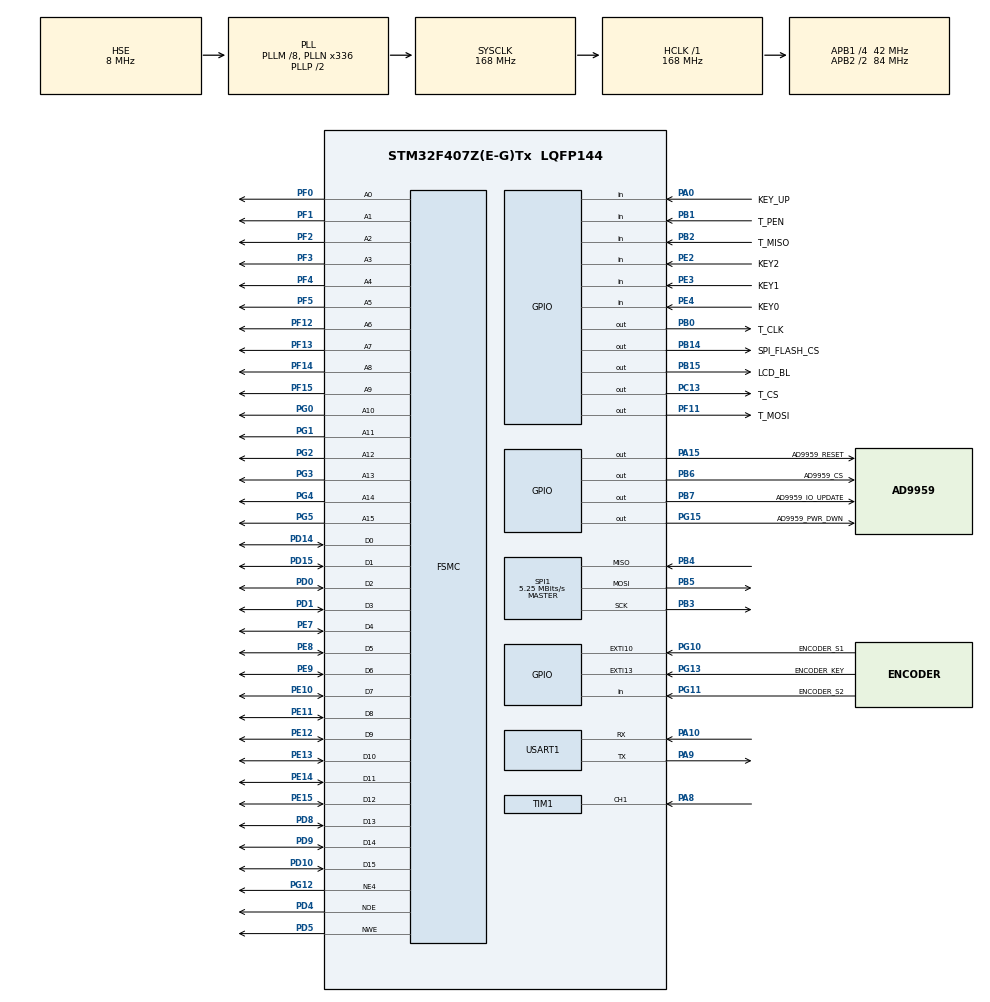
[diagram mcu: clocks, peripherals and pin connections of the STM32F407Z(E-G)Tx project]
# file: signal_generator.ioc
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FSMC.DataSetupTime4=60
FSMC.ExtendedAddressSetupTime4=9
FSMC.ExtendedDataSetupTime4=9
FSMC.ExtendedMode4=FSMC_EXTENDED_MODE_ENABLE
FSMC.WriteOperation4=FSMC_WRITE_OPERATION_ENABLE
Mcu.Family=STM32F4
Mcu.Name=STM32F407Z(E-G)Tx
Mcu.Package=LQFP144
NVIC.EXTI15_10_IRQn=true\:0\:0\:false\:false\:true\:true\:true\:true
NVIC.PriorityGroup=NVIC_PRIORITYGROUP_4
NVIC.TIM1_CC_IRQn=true\:0\:0\:false\:false\:true\:true\:true\:true
PA0-WKUP.GPIO_Label=KEY_UP
PA0-WKUP.GPIO_PuPd=GPIO_PULLDOWN
PA0-WKUP.Signal=GPIO_Input
PA10.Mode=Asynchronous
PA10.Signal=USART1_RX
PA13.Mode=Serial_Wire
PA13.Signal=SYS_JTMS-SWDIO
PA14.Mode=Serial_Wire
PA14.Signal=SYS_JTCK-SWCLK
PA15.GPIO_Label=AD9959_RESET
PA15.Signal=GPIO_Output
PA8.Signal=S_TIM1_CH1
PA9.Mode=Asynchronous
PA9.Signal=USART1_TX
PB0.GPIO_Label=T_CLK
PB0.GPIO_Speed=GPIO_SPEED_FREQ_HIGH
PB0.Signal=GPIO_Output
PB1.GPIO_Label=T_PEN
PB1.GPIO_PuPd=GPIO_PULLUP
PB1.Signal=GPIO_Input
PB14.GPIO_Label=SPI_FLASH_CS
PB14.PinState=GPIO_PIN_SET
PB14.Signal=GPIO_Output
PB15.GPIO_Label=LCD_BL
PB15.Signal=GPIO_Output
PB2.GPIO_Label=T_MISO
PB2.GPIO_PuPd=GPIO_PULLUP
PB2.Signal=GPIO_Input
PB3.Mode=Full_Duplex_Master
PB3.Signal=SPI1_SCK
PB4.Mode=Full_Duplex_Master
PB4.Signal=SPI1_MISO
PB4.Stacked=true
PB5.Mode=Full_Duplex_Master
PB5.Signal=SPI1_MOSI
PB6.GPIO_Label=AD9959_CS
PB6.PinState=GPIO_PIN_SET
PB6.Signal=GPIO_Output
PB7.GPIO_Label=AD9959_IO_UPDATE
PB7.PinState=GPIO_PIN_SET
PB7.Signal=GPIO_Output
PC13-ANTI_TAMP.GPIO_Label=T_CS
PC13-ANTI_TAMP.PinState=GPIO_PIN_SET
PC13-ANTI_TAMP.Signal=GPIO_Output
PC14-OSC32_IN.Mode=LSE-External-Oscillator
PC14-OSC32_IN.Signal=RCC_OSC32_IN
PC15-OSC32_OUT.Mode=LSE-External-Oscillator
PC15-OSC32_OUT.Signal=RCC_OSC32_OUT
PD0.Signal=FSMC_D2_DA2
PD1.Signal=FSMC_D3_DA3
PD10.Signal=FSMC_D15_DA15
PD14.Signal=FSMC_D0_DA0
PD15.Signal=FSMC_D1_DA1
PD4.Signal=FSMC_NOE
PD5.Signal=FSMC_NWE
PD8.Signal=FSMC_D13_DA13
PD9.Signal=FSMC_D14_DA14
PE10.Signal=FSMC_D7_DA7
PE11.Signal=FSMC_D8_DA8
PE12.Signal=FSMC_D9_DA9
PE13.Signal=FSMC_D10_DA10
PE14.Signal=FSMC_D11_DA11
PE15.Signal=FSMC_D12_DA12
PE2.GPIO_Label=KEY2
PE2.GPIO_PuPd=GPIO_PULLUP
PE2.Signal=GPIO_Input
PE3.GPIO_Label=KEY1
PE3.GPIO_PuPd=GPIO_PULLUP
PE3.Signal=GPIO_Input
PE4.GPIO_Label=KEY0
PE4.GPIO_PuPd=GPIO_PULLUP
PE4.Signal=GPIO_Input
PE7.Signal=FSMC_D4_DA4
PE8.Signal=FSMC_D5_DA5
PE9.Signal=FSMC_D6_DA6
PF0.Signal=FSMC_A0
PF1.Signal=FSMC_A1
PF11.GPIO_Label=T_MOSI
PF11.GPIO_Speed=GPIO_SPEED_FREQ_HIGH
PF11.Signal=GPIO_Output
PF12.Signal=FSMC_A6
PF13.Signal=FSMC_A7
PF14.Signal=FSMC_A8
PF15.Signal=FSMC_A9
PF2.Signal=FSMC_A2
PF3.Signal=FSMC_A3
PF4.Signal=FSMC_A4
PF5.Signal=FSMC_A5
PG0.Signal=FSMC_A10
PG1.Signal=FSMC_A11
PG10.GPIO_Label=ENCODER_S1
PG10.GPIO_ModeDefaultEXTI=GPIO_MODE_IT_FALLING
PG10.GPIO_PuPd=GPIO_PULLUP
PG10.Signal=GPXTI10
PG11.GPIO_Label=ENCODER_S2
PG11.GPIO_PuPd=GPIO_PULLUP
PG11.Signal=GPIO_Input
PG12.Mode=NorPsramChipSelect4_4
PG12.Signal=FSMC_NE4
PG13.GPIO_Label=ENCODER_KEY
PG13.GPIO_ModeDefaultEXTI=GPIO_MODE_IT_FALLING
PG13.GPIO_PuPd=GPIO_PULLUP
PG13.Signal=GPXTI13
PG15.GPIO_Label=AD9959_PWR_DWN
PG15.Signal=GPIO_Output
PG2.Signal=FSMC_A12
PG3.Signal=FSMC_A13
PG4.Signal=FSMC_A14
PG5.Signal=FSMC_A15
PH0-OSC_IN.Mode=HSE-External-Oscillator
PH0-OSC_IN.Signal=RCC_OSC_IN
PH1-OSC_OUT.Mode=HSE-External-Oscillator
PH1-OSC_OUT.Signal=RCC_OSC_OUT
ProjectManager.HeapSize=0x2000
ProjectManager.StackSize=0x4000
ProjectManager.TargetToolchain=CMake
RCC.48MHZClocksFreq_Value=84000000
RCC.AHBFreq_Value=168000000
RCC.APB1CLKDivider=RCC_HCLK_DIV4
RCC.APB1Freq_Value=42000000
RCC.APB1TimFreq_Value=84000000
RCC.APB2CLKDivider=RCC_HCLK_DIV2
RCC.APB2Freq_Value=84000000
RCC.APB2TimFreq_Value=168000000
RCC.CortexFreq_Value=168000000
RCC.HCLKFreq_Value=168000000
RCC.HSE_VALUE=8000000
RCC.HSI_VALUE=16000000
RCC.PLLM=8
RCC.PLLN=336
RCC.PLLSourceVirtual=RCC_PLLSOURCE_HSE
RCC.SYSCLKFreq_VALUE=168000000
RCC.SYSCLKSource=RCC_SYSCLKSOURCE_PLLCLK
RCC.VCOOutputFreq_Value=336000000
SH.FSMC_A0.0=FSMC_A0,16b-a4
SH.FSMC_A1.0=FSMC_A1,16b-a4
SH.FSMC_A10.0=FSMC_A10,16b-a4
SH.FSMC_A11.0=FSMC_A11,16b-a4
SH.FSMC_A12.0=FSMC_A12,16b-a4
SH.FSMC_A13.0=FSMC_A13,16b-a4
SH.FSMC_A14.0=FSMC_A14,16b-a4
SH.FSMC_A15.0=FSMC_A15,16b-a4
SH.FSMC_A2.0=FSMC_A2,16b-a4
SH.FSMC_A3.0=FSMC_A3,16b-a4
SH.FSMC_A4.0=FSMC_A4,16b-a4
SH.FSMC_A5.0=FSMC_A5,16b-a4
SH.FSMC_A6.0=FSMC_A6,16b-a4
SH.FSMC_A7.0=FSMC_A7,16b-a4
SH.FSMC_A8.0=FSMC_A8,16b-a4
SH.FSMC_A9.0=FSMC_A9,16b-a4
SH.FSMC_D0_DA0.0=FSMC_D0,16b-d4
SH.FSMC_D10_DA10.0=FSMC_D10,16b-d4
SH.FSMC_D11_DA11.0=FSMC_D11,16b-d4
SH.FSMC_D12_DA12.0=FSMC_D12,16b-d4
SH.FSMC_D13_DA13.0=FSMC_D13,16b-d4
SH.FSMC_D14_DA14.0=FSMC_D14,16b-d4
SH.FSMC_D15_DA15.0=FSMC_D15,16b-d4
SH.FSMC_D1_DA1.0=FSMC_D1,16b-d4
SH.FSMC_D2_DA2.0=FSMC_D2,16b-d4
SH.FSMC_D3_DA3.0=FSMC_D3,16b-d4
SH.FSMC_D4_DA4.0=FSMC_D4,16b-d4
SH.FSMC_D5_DA5.0=FSMC_D5,16b-d4
SH.FSMC_D6_DA6.0=FSMC_D6,16b-d4
SH.FSMC_D7_DA7.0=FSMC_D7,16b-d4
SH.FSMC_D8_DA8.0=FSMC_D8,16b-d4
SH.FSMC_D9_DA9.0=FSMC_D9,16b-d4
SH.FSMC_NOE.0=FSMC_NOE,Sram4
SH.FSMC_NWE.0=FSMC_NWE,Sram4
SH.S_TIM1_CH1.0=TIM1_CH1,Input_Capture1_from_TI1
SPI1.BaudRatePrescaler=SPI_BAUDRATEPRESCALER_16
SPI1.CalculateBaudRate=5.25 MBits/s
SPI1.Direction=SPI_DIRECTION_2LINES
SPI1.Mode=SPI_MODE_MASTER
SPI1.VirtualType=VM_MASTER
TIM1.Channel-Input_Capture1_from_TI1=TIM_CHANNEL_1
TIM1.ICPrescaler-Input_Capture1_from_TI1=TIM_ICPSC_DIV1
TIM1.Prescaler=71
USART1.VirtualMode=VM_ASYNC
board=custom

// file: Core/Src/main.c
/* USER CODE BEGIN Header */
/**
  ******************************************************************************
  * @file           : main.c
  * @brief          : Main program body
  ******************************************************************************
  * @attention
  *
  * Copyright (c) 2026 STMicroelectronics.
  * All rights reserved.
  *
  * This software is licensed under terms that can be found in the LICENSE file
  * in the root directory of this software component.
  * If no LICENSE file comes with this software, it is provided AS-IS.
  *
  ******************************************************************************
  */
/* USER CODE END Header */
#include "main.h"
#include "spi.h"
#include "tim.h"
#include "usart.h"
#include "gpio.h"
#include "fsmc.h"

/* USER CODE BEGIN Includes */
#include "app_signal_generator.h"

/* USER CODE END Includes */

void SystemClock_Config(void);

int main(void)
{

  /* MCU Configuration--------------------------------------------------------*/

  /* Reset of all peripherals, Initializes the Flash interface and the Systick. */
  HAL_Init();

  /* Configure the system clock */
  SystemClock_Config();

  /* Initialize all configured peripherals */
  MX_GPIO_Init();
  MX_FSMC_Init();
  MX_SPI1_Init();
  MX_USART1_UART_Init();
  MX_TIM1_Init();
  /* USER CODE BEGIN 2 */
  if (App_SignalGenerator_Init() == 0U)
  {
    Error_Handler();
  }

  /* USER CODE END 2 */

  /* Infinite loop */
  while (1)
  {

    /* USER CODE BEGIN 3 */
    App_SignalGenerator_Process();
  }
  /* USER CODE END 3 */
}

void SystemClock_Config(void)
{
  RCC_OscInitTypeDef RCC_OscInitStruct = {0};
  RCC_ClkInitTypeDef RCC_ClkInitStruct = {0};

  /** Configure the main internal regulator output voltage
  */
  __HAL_RCC_PWR_CLK_ENABLE();
  __HAL_PWR_VOLTAGESCALING_CONFIG(PWR_REGULATOR_VOLTAGE_SCALE1);

  /** Initializes the RCC Oscillators according to the specified parameters
  * in the RCC_OscInitTypeDef structure.
  */
  RCC_OscInitStruct.OscillatorType = RCC_OSCILLATORTYPE_HSE;
  RCC_OscInitStruct.HSEState = RCC_HSE_ON;
  RCC_OscInitStruct.PLL.PLLState = RCC_PLL_ON;
  RCC_OscInitStruct.PLL.PLLSource = RCC_PLLSOURCE_HSE;
  RCC_OscInitStruct.PLL.PLLM = 8;
  RCC_OscInitStruct.PLL.PLLN = 336;
  RCC_OscInitStruct.PLL.PLLP = RCC_PLLP_DIV2;
  RCC_OscInitStruct.PLL.PLLQ = 4;
  if (HAL_RCC_OscConfig(&RCC_OscInitStruct) != HAL_OK)
  {
    Error_Handler();
  }

  /** Initializes the CPU, AHB and APB buses clocks
  */
  RCC_ClkInitStruct.ClockType = RCC_CLOCKTYPE_HCLK|RCC_CLOCKTYPE_SYSCLK
                              |RCC_CLOCKTYPE_PCLK1|RCC_CLOCKTYPE_PCLK2;
  RCC_ClkInitStruct.SYSCLKSource = RCC_SYSCLKSOURCE_PLLCLK;
  RCC_ClkInitStruct.AHBCLKDivider = RCC_SYSCLK_DIV1;
  RCC_ClkInitStruct.APB1CLKDivider = RCC_HCLK_DIV4;
  RCC_ClkInitStruct.APB2CLKDivider = RCC_HCLK_DIV2;

  if (HAL_RCC_ClockConfig(&RCC_ClkInitStruct, FLASH_LATENCY_5) != HAL_OK)
  {
    Error_Handler();
  }
}

void Error_Handler(void)
{
  __disable_irq();
  while (1)
  {
  }
}
